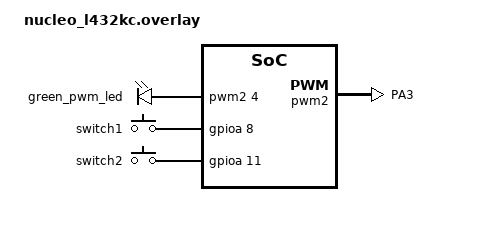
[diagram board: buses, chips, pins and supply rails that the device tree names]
/{
    pwmleds: pwmleds {
        compatible = "pwm-leds";
        status = "okay";
        green_pwm_led: green_pwm_led {
            pwms = <&pwm2 4 PWM_MSEC(20) PWM_POLARITY_NORMAL>; // &pwm2 links to TIM2_CH4 and PA3
        };
    };
    
    /* GPIO Inputs for switches */
    gpio_inputs {
        compatible = "gpio-keys";
        switch1: switch1 {
            gpios = <&gpioa 8 (GPIO_PULL_DOWN | GPIO_ACTIVE_HIGH)>; // PA8 -> D9
        };
        switch2: switch2 {
            gpios = <&gpioa 11 (GPIO_PULL_DOWN | GPIO_ACTIVE_HIGH)>; // PA11 -> D10
        };
    };
};

&pwm2 {
    status = "okay";
    pinctrl-0 = <&pwm2_custom>;
};

&pinctrl {
    pwm2_custom: pwm2_custom {
        pinmux = <STM32_PINMUX('A', 3, AF1)>; // Alternative function AF1 for this pin
    };
};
